# CH32F203xx register map
Vendor: WCH Ltd.; File version: 1.0
Registers are 32-bit, read-write, reset 0x0 unless marked. A register's access mark holds for its fields unless they carry their own. Offsets are from the block's base; [hi:lo] are bit positions.

## DVP — Digital Video Port
Base 0x50050000
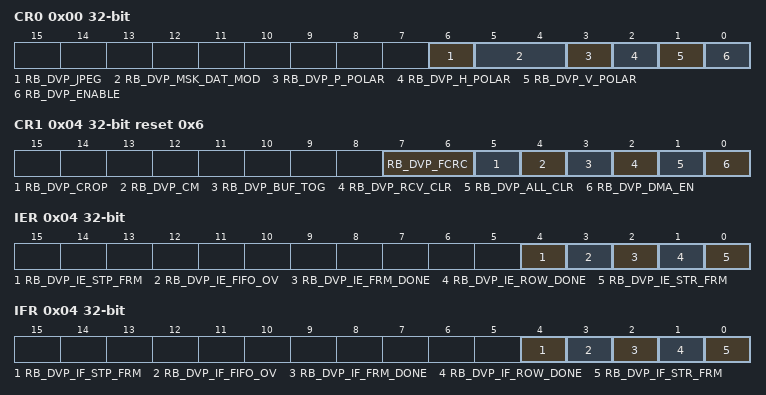
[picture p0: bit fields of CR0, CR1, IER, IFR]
0x00 CR0 access not given — Digital Video control register (DVP_CR0)
  [6] RB_DVP_JPEG — DVP JPEG mode
  [5:4] RB_DVP_MSK_DAT_MOD — DVP data mode
  [3] RB_DVP_P_POLAR — DVP PCLK polarity control
  [2] RB_DVP_H_POLAR — DVP HSYNC polarity control
  [1] RB_DVP_V_POLAR — DVP VSYNC polarity control
  [0] RB_DVP_ENABLE — DVP enable
0x04 CR1 access not given reset 0x6 — Digital Video control register (DVP_CR1)
  [7:6] RB_DVP_FCRC — DVP frame capture rate control
  [5] RB_DVP_CROP — DVP Crop feature enable
  [4] RB_DVP_CM — DVP capture mode
  [3] RB_DVP_BUF_TOG — DVP bug toggle by software
  [2] RB_DVP_RCV_CLR — DVP receive logic clear
  [1] RB_DVP_ALL_CLR — DVP all clear
  [0] RB_DVP_DMA_EN — DVP dma enable
0x04 IER access not given — Digital Video Interrupt register (DVP_IER)
  [4] RB_DVP_IE_STP_FRM — DVP frame stop interrupt enable
  [3] RB_DVP_IE_FIFO_OV — DVP receive fifo overflow interrupt enable
  [2] RB_DVP_IE_FRM_DONE — DVP frame received done interrupt enable
  [1] RB_DVP_IE_ROW_DONE — DVP row received done interrupt enable
  [0] RB_DVP_IE_STR_FRM — DVP frame start interrupt enable
0x04 IFR access not given — Digital Video Flag register (DVP_IFR)
  [4] RB_DVP_IF_STP_FRM — DVP frame stop interrupt enable
  [3] RB_DVP_IF_FIFO_OV — DVP receive fifo overflow interrupt enable
  [2] RB_DVP_IF_FRM_DONE — DVP frame received done interrupt enable
  [1] RB_DVP_IF_ROW_DONE — DVP row received done interrupt enable
  [0] RB_DVP_IF_STR_FRM — DVP frame start interrupt enable
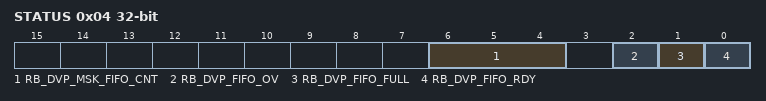
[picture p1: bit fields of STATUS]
0x04 STATUS access not given — Digital Video STATUS register (DVP_STATUS)
  [6:4] RB_DVP_MSK_FIFO_CNT — DVP receive fifo overflow interrupt enable
  [2] RB_DVP_FIFO_OV — DVP frame received done interrupt enable
  [1] RB_DVP_FIFO_FULL — DVP row received done interrupt enable
  [0] RB_DVP_FIFO_RDY — DVP frame start interrupt enable

## DAC — Digital to analog converter
Base 0x40007400
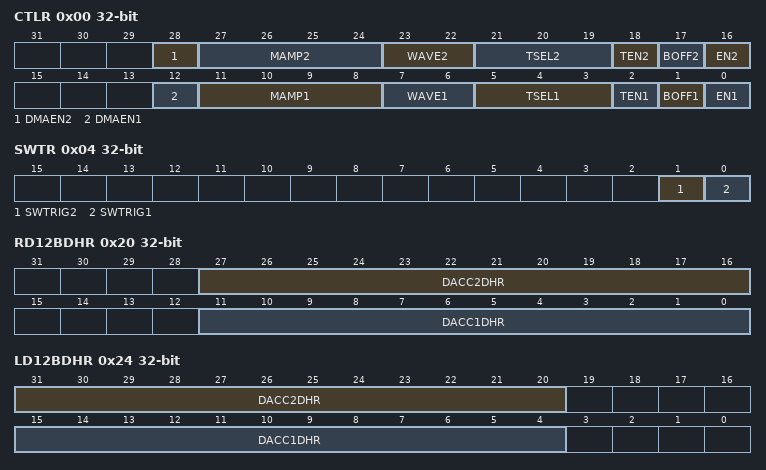
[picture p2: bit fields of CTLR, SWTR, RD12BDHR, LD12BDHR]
0x00 CTLR — Control register (DAC_CR)
  [28] DMAEN2 — DAC channel2 DMA enable
  [27:24] MAMP2 — DAC channel2 mask/amplitude selector
  [23:22] WAVE2 — DAC channel2 noise/triangle wave generation enable
  [21:19] TSEL2 — DAC channel2 trigger selection
  [18] TEN2 — DAC channel2 trigger enable
  [17] BOFF2 — DAC channel2 output buffer disable
  [16] EN2 — DAC channel2 enable
  [12] DMAEN1 — DAC channel1 DMA enable
  [11:8] MAMP1 — DAC channel1 mask/amplitude selector
  [7:6] WAVE1 — DAC channel1 noise/triangle wave generation enable
  [5:3] TSEL1 — DAC channel1 trigger selection
  [2] TEN1 — DAC channel1 trigger enable
  [1] BOFF1 — DAC channel1 output buffer disable
  [0] EN1 — DAC channel1 enable
0x04 SWTR wo — DAC software trigger register (DAC_SWTRIGR)
  [1] SWTRIG2 — DAC channel2 software trigger
  [0] SWTRIG1 — DAC channel1 software trigger
0x08 R12BDHR1 — DAC channel1 12-bit right-aligned data holding register(DAC_DHR12R1)
  [11:0] DACC1DHR — DAC channel1 12-bit right-aligned data
0x0C L12BDHR1 — DAC channel1 12-bit left aligned data holding register (DAC_DHR12L1)
  [15:4] DACC1DHR — DAC channel1 12-bit left-aligned data
0x10 R8BDHR1 — DAC channel1 8-bit right aligned data holding register (DAC_DHR8R1)
  [7:0] DACC1DHR — DAC channel1 8-bit right-aligned data
0x14 R12BDHR2 — DAC channel2 12-bit right aligned data holding register (DAC_DHR12R2)
  [11:0] DACC2DHR — DAC channel2 12-bit right-aligned data
0x18 L12BDHR2 — DAC channel2 12-bit left aligned data holding register (DAC_DHR12L2)
  [15:4] DACC2DHR — DAC channel2 12-bit left-aligned data
0x1C R8BDHR2 — DAC channel2 8-bit right-aligned data holding register (DAC_DHR8R2)
  [7:0] DACC2DHR — DAC channel2 8-bit right-aligned data
0x20 RD12BDHR — Dual DAC 12-bit right-aligned data holding register (DAC_DHR12RD), Bits 31:28 Reserved, Bits 15:12 Reserved
  [27:16] DACC2DHR — DAC channel2 12-bit right-aligned data
  [11:0] DACC1DHR — DAC channel1 12-bit right-aligned data
0x24 LD12BDHR — DUAL DAC 12-bit left aligned data holding register (DAC_DHR12LD), Bits 19:16 Reserved, Bits 3:0 Reserved
  [31:20] DACC2DHR — DAC channel2 12-bit right-aligned data
  [15:4] DACC1DHR — DAC channel1 12-bit left-aligned data
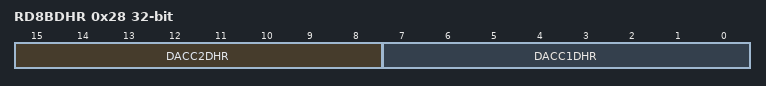
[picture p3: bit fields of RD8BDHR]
0x28 RD8BDHR — DUAL DAC 8-bit right aligned data holding register (DAC_DHR8RD), Bits 31:16 Reserved
  [15:8] DACC2DHR — DAC channel2 8-bit right-aligned data
  [7:0] DACC1DHR — DAC channel1 8-bit right-aligned data
0x2C DOR1 ro — DAC channel1 data output register (DAC_DOR1)
  [11:0] DACC1DOR — DAC channel1 data output
0x30 DOR2 ro — DAC channel2 data output register (DAC_DOR2)
  [11:0] DACC2DOR — DAC channel2 data output
